VERSION ""

NS_ :

BS_:

BU_:

BO_ 2566840574 VHLDIST: 8 Vector__XXX
 SG_ TripDistance : 0|32@1+ (0.125,0) [0|536870911.875] "Kms" Vector__XXX
 SG_ TotalVehicleDistance : 32|32@1+ (0.125,0) [0|536870911.875] "Kms" Vector__XXX

BO_ 2365484065 VSPD: 8 Vector__XXX
 SG_ VehicleSpeed : 48|16@1+ (0.00390625,0) [0|250.99609375] "Kmph" Vector__XXX

BO_ 2566846208 BTRY: 8 Vector__XXX
 SG_ BatteryVoltage : 32|16@1+ (0.05,0) [0|3276.75] "V" Vector__XXX

BO_ 2566845696 INTKTEMP: 8 Vector__XXX
 SG_ EngineIntakeAirTemp : 40|8@1+ (1,-40) [-40|210] "degC" Vector__XXX

BO_ 2566843904 ENGOLTEMP: 8 Vector__XXX
 SG_ CoolantTemperature : 0|8@1- (1,-40) [-40|210] "degC" Vector__XXX
 SG_ EngineOilTemperature : 16|16@1+ (0.03125,-273) [-273|1774.96875] "degC" Vector__XXX

BO_ 2566845952 MNPR: 8 Vector__XXX
 SG_ EngineInItakeManifoldPressure : 8|8@1+ (2,0) [0|500] "kPa" Vector__XXX

BO_ 2566827553 AIRPR: 8 Vector__XXX
 SG_ RightBrakePressure : 16|8@1+ (8,0) [0|2000] "Kpa" Vector__XXX
 SG_ LeftBrakePressure : 24|8@1+ (8,0) [0|2000] "Kpa" Vector__XXX

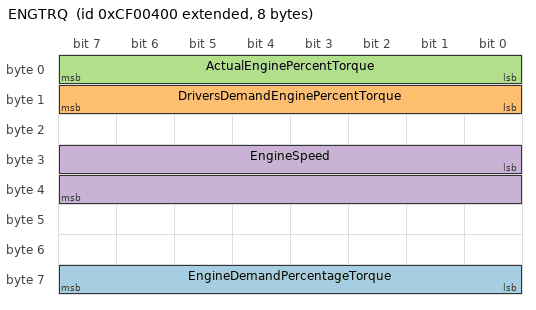
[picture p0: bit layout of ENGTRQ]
BO_ 2364539904 ENGTRQ: 8 Vector__XXX
 SG_ EngineDemandPercentageTorque : 56|8@1+ (1,-125) [-125|130] "%" Vector__XXX
 SG_ DriversDemandEnginePercentTorque : 8|8@1+ (1,-125) [-125|-125] "%" Vector__XXX
 SG_ ActualEnginePercentTorque : 0|8@1+ (1,-125) [-125|125] "%" Vector__XXX
 SG_ EngineSpeed : 24|16@1+ (0.125,0) [0|8191.875] "rpm" Vector__XXX

BO_ 2364539648 TRQAP: 8 Vector__XXX
 SG_ EnginePercentLoadAtCurrentSpeed : 16|8@1+ (1,0) [0|250] "%" Vector__XXX
 SG_ AcceleratorPedalPosition : 8|8@1+ (0.4,0) [0|100] "%" Vector__XXX

BA_DEF_ SG_  "SigType" ENUM  "Default","Range","RangeSigned","ASCII","Discrete","Control","ReferencePGN","DTC","StringDelimiter","StringLength","StringLengthControl","MessageCounter","MessageChecksum";
BA_DEF_ SG_  "GenSigEVName" STRING ;
BA_DEF_ SG_  "GenSigILSupport" ENUM  "No","Yes";
BA_DEF_ SG_  "GenSigSendType" ENUM  "Cyclic","OnWrite","OnWriteWithRepetition","OnChange","OnChangeWithRepetition","IfActive","IfActiveWithRepetition","NoSigSendType";
BA_DEF_ SG_  "GenSigStartValue" INT 0 10000;
BA_DEF_ BO_  "GenMsgILSupport" ENUM  "No","Yes";
BA_DEF_ BU_  "NmStationAddress" INT 0 255;
BA_DEF_ BO_  "GenMsgSendType" ENUM  "cyclic","NotUsed","IfActive","NotUsed","NotUsed","NotUsed","NotUsed","NotUsed","noMsgSendType";
BA_DEF_ BO_  "GenMsgRequestable" INT 0 1;
BA_DEF_  "DBName" STRING ;
BA_DEF_  "BusType" STRING ;
BA_DEF_  "ProtocolType" STRING ;
BA_DEF_ BO_  "VFrameFormat" ENUM  "StandardCAN","ExtendedCAN","reserved","J1939PG";
BA_DEF_DEF_  "SigType" "Default";
BA_DEF_DEF_  "GenSigEVName" "Env@Nodename_@Signame";
BA_DEF_DEF_  "GenSigILSupport" "Yes";
BA_DEF_DEF_  "GenSigSendType" "NoSigSendType";
BA_DEF_DEF_  "GenSigStartValue" 0;
BA_DEF_DEF_  "GenMsgILSupport" "Yes";
BA_DEF_DEF_  "NmStationAddress" 254;
BA_DEF_DEF_  "GenMsgSendType" "noMsgSendType";
BA_DEF_DEF_  "GenMsgRequestable" 1;
BA_DEF_DEF_  "DBName" "";
BA_DEF_DEF_  "BusType" "CAN";
BA_DEF_DEF_  "ProtocolType" "J1939";
BA_DEF_DEF_  "VFrameFormat" "J1939PG";
BA_ "DBName" "TATA MARCOPOLO CNG";
BA_ "GenSigStartValue" SG_ 2566845696 EngineIntakeAirTemp 40;
BA_ "GenSigStartValue" SG_ 2566843904 CoolantTemperature 40;
BA_ "GenSigStartValue" SG_ 2566843904 EngineOilTemperature 8736;
